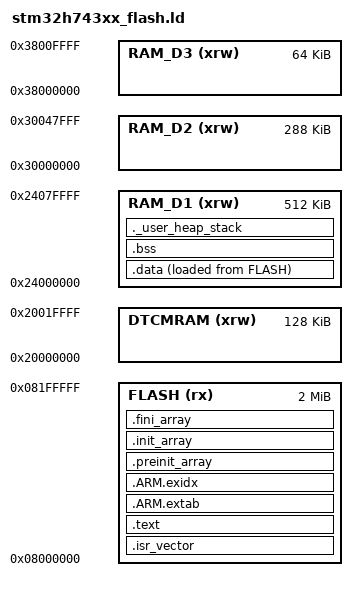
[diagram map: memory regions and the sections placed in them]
ENTRY(Reset_Handler)

MEMORY
{
    FLASH (rx)  : ORIGIN = 0x08000000, LENGTH = 2048K
    DTCMRAM (xrw) : ORIGIN = 0x20000000, LENGTH = 128K
    RAM_D1 (xrw) : ORIGIN = 0x24000000, LENGTH = 512K
    RAM_D2 (xrw) : ORIGIN = 0x30000000, LENGTH = 288K
    RAM_D3 (xrw) : ORIGIN = 0x38000000, LENGTH = 64K
}

_estack = ORIGIN(RAM_D1) + LENGTH(RAM_D1);

SECTIONS
{
    .isr_vector :
    {
        KEEP(*(.isr_vector))
    } > FLASH

    .text :
    {
        *(.text*)
        *(.rodata*)
        KEEP(*(.init))
        KEEP(*(.fini))
        . = ALIGN(4);
    } > FLASH

    .ARM.extab :
    {
        *(.ARM.extab* .gnu.linkonce.armextab.*)
    } > FLASH

    .ARM.exidx :
    {
        __exidx_start = .;
        *(.ARM.exidx* .gnu.linkonce.armexidx.*)
        __exidx_end = .;
    } > FLASH

    .preinit_array :
    {
        PROVIDE_HIDDEN(__preinit_array_start = .);
        KEEP(*(.preinit_array*))
        PROVIDE_HIDDEN(__preinit_array_end = .);
    } > FLASH

    .init_array :
    {
        PROVIDE_HIDDEN(__init_array_start = .);
        KEEP(*(SORT(.init_array.*)))
        KEEP(*(.init_array*))
        PROVIDE_HIDDEN(__init_array_end = .);
    } > FLASH

    .fini_array :
    {
        PROVIDE_HIDDEN(__fini_array_start = .);
        KEEP(*(SORT(.fini_array.*)))
        KEEP(*(.fini_array*))
        PROVIDE_HIDDEN(__fini_array_end = .);
    } > FLASH

    _sidata = LOADADDR(.data);

    .data :
    {
        _sdata = .;
        *(.data*)
        . = ALIGN(4);
        _edata = .;
    } > RAM_D1 AT > FLASH

    .bss :
    {
        _sbss = .;
        *(.bss*)
        *(COMMON)
        . = ALIGN(4);
        _ebss = .;
    } > RAM_D1

    ._user_heap_stack :
    {
        . = ALIGN(8);
        PROVIDE(end = .);
        PROVIDE(_end = .);
        PROVIDE(_heap_start = .);
        . = . + 32K;
        PROVIDE(_heap_end = .);
        . = . + 32K;
        . = ALIGN(8);
    } > RAM_D1
}
